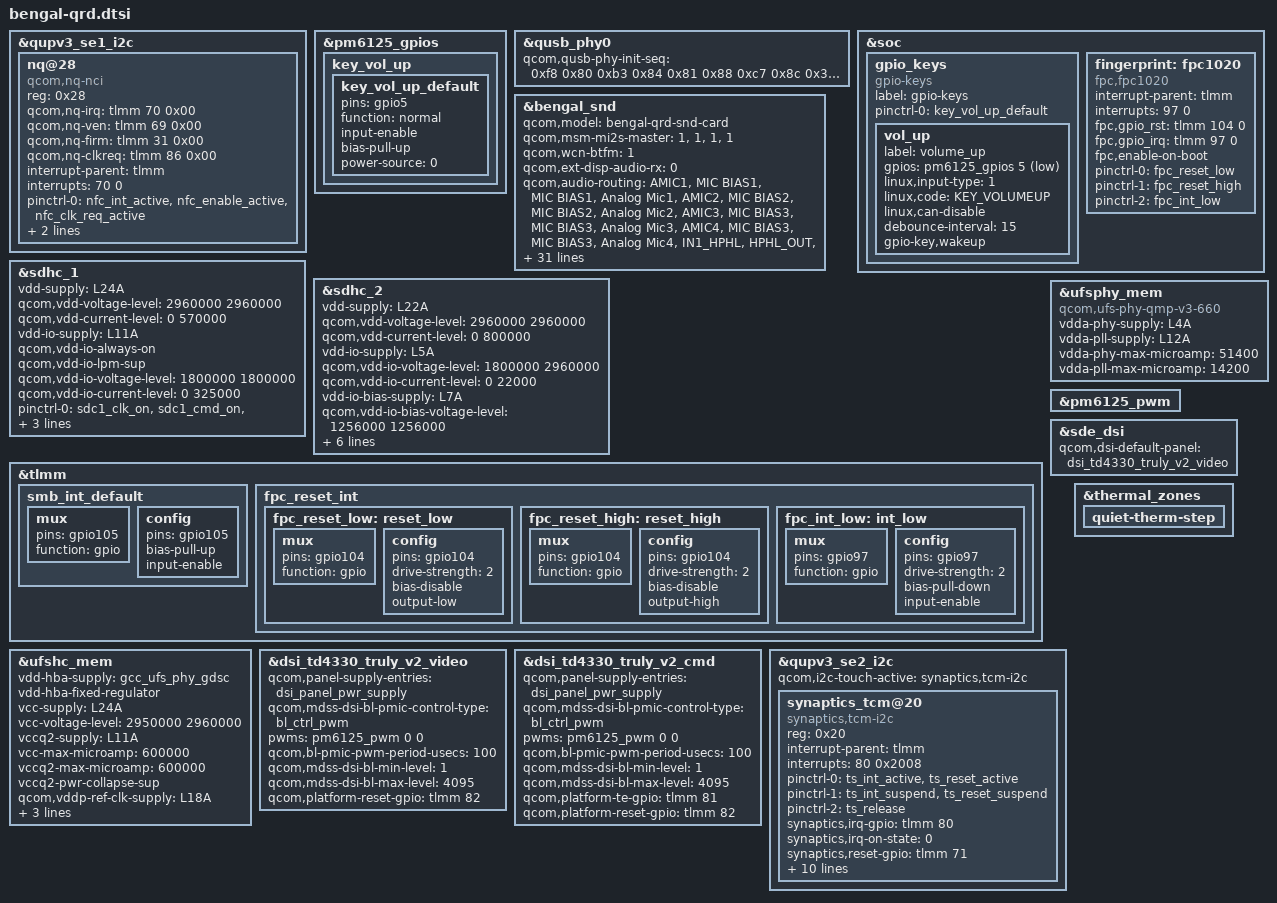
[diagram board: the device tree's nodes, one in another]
#include <dt-bindings/gpio/gpio.h>
#include <dt-bindings/iio/qcom,spmi-vadc.h>
#include <dt-bindings/input/input.h>
#include "bengal-thermal-overlay.dtsi"
#include "bengal-audio-overlay.dtsi"
#include "bengal-sde-display.dtsi"
#include "camera/bengal-camera-sensor-qrd.dtsi"

&qupv3_se1_i2c {
	status = "ok";
	#include "smb1355.dtsi"
};

&pm6125_gpios {
	key_vol_up {
		key_vol_up_default: key_vol_up_default {
			pins = "gpio5";
			function = "normal";
			input-enable;
			bias-pull-up;
			power-source = <0>;
		};
	};
};

&qusb_phy0 {
	qcom,qusb-phy-init-seq = <0xf8 0x80
				0xb3 0x84
				0x81 0x88
				0xc7 0x8c
				0x30 0x08
				0x79 0x0c
				0x21 0x10
				0x14 0x9c
				0x80 0x04
				0x9f 0x1c
				0x00 0x18>;
};

&soc {
	gpio_keys {
		compatible = "gpio-keys";
		label = "gpio-keys";

		pinctrl-names = "default";
		pinctrl-0 = <&key_vol_up_default>;

		vol_up {
			label = "volume_up";
			gpios = <&pm6125_gpios 5 GPIO_ACTIVE_LOW>;
			linux,input-type = <1>;
			linux,code = <KEY_VOLUMEUP>;
			linux,can-disable;
			debounce-interval = <15>;
			gpio-key,wakeup;
		};
	};
};

&bengal_snd {
	qcom,model = "bengal-qrd-snd-card";
	qcom,msm-mi2s-master = <1>, <1>, <1>, <1>;
	qcom,wcn-btfm = <1>;
	qcom,ext-disp-audio-rx = <0>;
	qcom,audio-routing =
		"AMIC1", "MIC BIAS1",
		"MIC BIAS1", "Analog Mic1",
		"AMIC2", "MIC BIAS2",
		"MIC BIAS2", "Analog Mic2",
		"AMIC3", "MIC BIAS3",
		"MIC BIAS3", "Analog Mic3",
		"AMIC4", "MIC BIAS3",
		"MIC BIAS3", "Analog Mic4",
		"IN1_HPHL", "HPHL_OUT",
		"IN2_HPHR", "HPHR_OUT",
		"IN3_AUX", "AUX_OUT",
		"SpkrMono WSA_IN", "AUX",
		"TX SWR_MIC0", "ADC1_OUTPUT",
		"TX SWR_MIC4", "ADC2_OUTPUT",
		"TX SWR_MIC5", "ADC3_OUTPUT",
		"TX SWR_MIC0", "VA_TX_SWR_CLK",
		"TX SWR_MIC1", "VA_TX_SWR_CLK",
		"TX SWR_MIC2", "VA_TX_SWR_CLK",
		"TX SWR_MIC3", "VA_TX_SWR_CLK",
		"TX SWR_MIC4", "VA_TX_SWR_CLK",
		"TX SWR_MIC5", "VA_TX_SWR_CLK",
		"TX SWR_MIC6", "VA_TX_SWR_CLK",
		"TX SWR_MIC7", "VA_TX_SWR_CLK",
		"TX SWR_MIC8", "VA_TX_SWR_CLK",
		"TX SWR_MIC9", "VA_TX_SWR_CLK",
		"TX SWR_MIC10", "VA_TX_SWR_CLK",
		"TX SWR_MIC11", "VA_TX_SWR_CLK",
		"RX_TX DEC0_INP", "TX DEC0 MUX",
		"RX_TX DEC1_INP", "TX DEC1 MUX",
		"RX_TX DEC2_INP", "TX DEC2 MUX",
		"RX_TX DEC3_INP", "TX DEC3 MUX",
		"TX_AIF1 CAP", "VA_TX_SWR_CLK",
		"TX_AIF2 CAP", "VA_TX_SWR_CLK",
		"TX_AIF3 CAP", "VA_TX_SWR_CLK",
		"VA SWR_MIC0", "ADC1_OUTPUT",
		"VA SWR_MIC4", "ADC2_OUTPUT",
		"VA SWR_MIC5", "ADC3_OUTPUT";
	qcom,msm-mbhc-hphl-swh = <1>;
	qcom,msm-mbhc-gnd-swh = <1>;
	asoc-codec  = <&stub_codec>, <&bolero>;
	asoc-codec-names = "msm-stub-codec.1", "bolero_codec";
	qcom,wsa-max-devs = <1>;
	qcom,wsa-devs = <&wsa881x_i2c_e>;
	qcom,wsa-aux-dev-prefix = "SpkrMono";
	qcom,codec-max-aux-devs = <1>;
	qcom,codec-aux-devs = <&wcd937x_codec>;
	qcom,msm_audio_ssr_devs = <&audio_apr>, <&q6core>, <&bolero>,
				<&lpi_tlmm>;
};

&qupv3_se1_i2c {
	status = "ok";
	#address-cells = <1>;
	#size-cells = <0>;
	nq@28 {
		compatible = "qcom,nq-nci";
		reg = <0x28>;
		qcom,nq-irq = <&tlmm 70 0x00>;
		qcom,nq-ven = <&tlmm 69 0x00>;
		qcom,nq-firm = <&tlmm 31 0x00>;
		qcom,nq-clkreq = <&tlmm 86 0x00>;
		interrupt-parent = <&tlmm>;
		interrupts = <70 0>;
		interrupt-names = "nfc_irq";
		pinctrl-names = "nfc_active", "nfc_suspend";
		pinctrl-0 = <&nfc_int_active &nfc_enable_active
				&nfc_clk_req_active>;
		pinctrl-1 = <&nfc_int_suspend &nfc_enable_suspend
				&nfc_clk_req_suspend>;
	};
};

&sdhc_1 {
	vdd-supply = <&L24A>;
	qcom,vdd-voltage-level = <2960000 2960000>;
	qcom,vdd-current-level = <0 570000>;

	vdd-io-supply = <&L11A>;
	qcom,vdd-io-always-on;
	qcom,vdd-io-lpm-sup;
	qcom,vdd-io-voltage-level = <1800000 1800000>;
	qcom,vdd-io-current-level = <0 325000>;

	pinctrl-names = "active", "sleep";
	pinctrl-0 = <&sdc1_clk_on &sdc1_cmd_on &sdc1_data_on
					&sdc1_rclk_on>;
	pinctrl-1 = <&sdc1_clk_off &sdc1_cmd_off &sdc1_data_off
					&sdc1_rclk_off>;

	status = "ok";
};

&sdhc_2 {
	vdd-supply = <&L22A>;
	qcom,vdd-voltage-level = <2960000 2960000>;
	qcom,vdd-current-level = <0 800000>;

	vdd-io-supply = <&L5A>;
	qcom,vdd-io-voltage-level = <1800000 2960000>;
	qcom,vdd-io-current-level = <0 22000>;

	vdd-io-bias-supply = <&L7A>;
	qcom,vdd-io-bias-voltage-level = <1256000 1256000>;
	qcom,vdd-io-bias-current-level = <0 6000>;

	pinctrl-names = "active", "sleep";
	pinctrl-0 = <&sdc2_clk_on  &sdc2_cmd_on &sdc2_data_on &sdc2_cd_on>;
	pinctrl-1 = <&sdc2_clk_off &sdc2_cmd_off &sdc2_data_off &sdc2_cd_off>;

	cd-gpios = <&tlmm 88 GPIO_ACTIVE_LOW>;

	status = "ok";
};

&tlmm {
	smb_int_default: smb_int_default {
		mux {
			pins = "gpio105";
			function = "gpio";
		};

		config {
			pins = "gpio105";
			bias-pull-up;
			input-enable;
		};
	};
};

&ufsphy_mem {
	compatible = "qcom,ufs-phy-qmp-v3-660";

	vdda-phy-supply = <&L4A>; /* 0.9v */
	vdda-pll-supply = <&L12A>; /* 1.8v */
	vdda-phy-max-microamp = <51400>;
	vdda-pll-max-microamp = <14200>;

	status = "ok";
};

&ufshc_mem {
	vdd-hba-supply = <&gcc_ufs_phy_gdsc>;
	vdd-hba-fixed-regulator;
	vcc-supply = <&L24A>;
	vcc-voltage-level = <2950000 2960000>;
	vccq2-supply = <&L11A>;
	vcc-max-microamp = <600000>;
	vccq2-max-microamp = <600000>;
	vccq2-pwr-collapse-sup;

	qcom,vddp-ref-clk-supply = <&L18A>;
	qcom,vddp-ref-clk-max-microamp = <100>;
	qcom,vddp-ref-clk-min-uV = <1232000>;
	qcom,vddp-ref-clk-max-uV = <1232000>;

	status = "ok";
};

&pm6125_pwm {
	status = "ok";
};

&dsi_td4330_truly_v2_video {
	qcom,panel-supply-entries = <&dsi_panel_pwr_supply>;
	qcom,mdss-dsi-bl-pmic-control-type = "bl_ctrl_pwm";
	pwms = <&pm6125_pwm 0 0>;
	qcom,bl-pmic-pwm-period-usecs = <100>;
	qcom,mdss-dsi-bl-min-level = <1>;
	qcom,mdss-dsi-bl-max-level = <4095>;
	qcom,platform-reset-gpio = <&tlmm 82 0>;
};

&dsi_td4330_truly_v2_cmd {
	qcom,panel-supply-entries = <&dsi_panel_pwr_supply>;
	qcom,mdss-dsi-bl-pmic-control-type = "bl_ctrl_pwm";
	pwms = <&pm6125_pwm 0 0>;
	qcom,bl-pmic-pwm-period-usecs = <100>;
	qcom,mdss-dsi-bl-min-level = <1>;
	qcom,mdss-dsi-bl-max-level = <4095>;
	qcom,platform-te-gpio = <&tlmm 81 0>;
	qcom,platform-reset-gpio = <&tlmm 82 0>;
};

&sde_dsi {
	qcom,dsi-default-panel = <&dsi_td4330_truly_v2_video>;
};

&qupv3_se2_i2c {
	status = "okay";
	qcom,i2c-touch-active="synaptics,tcm-i2c";

	synaptics_tcm@20 {
		compatible = "synaptics,tcm-i2c";
		reg = <0x20>;
		interrupt-parent = <&tlmm>;
		interrupts = <80 0x2008>;
		pinctrl-names = "pmx_ts_active","pmx_ts_suspend",
			"pmx_ts_release";
		pinctrl-0 = <&ts_int_active &ts_reset_active>;
		pinctrl-1 = <&ts_int_suspend &ts_reset_suspend>;
		pinctrl-2 = <&ts_release>;
		synaptics,irq-gpio = <&tlmm 80 0x2008>;
		synaptics,irq-on-state = <0>;
		synaptics,reset-gpio = <&tlmm 71 0x00>;
		synaptics,reset-on-state = <0>;
		synaptics,reset-active-ms = <20>;
		synaptics,reset-delay-ms = <200>;
		synaptics,power-delay-ms = <200>;
		synaptics,ubl-i2c-addr = <0x20>;
		synaptics,extend_report;
		synaptics,firmware-name = "synaptics_firmware_k.img";

		panel = <&dsi_td4330_truly_v2_video &dsi_td4330_truly_v2_cmd>;
	};
};

&thermal_zones {
	quiet-therm-step {
		status = "ok";
	};
};

&tlmm {
	fpc_reset_int: fpc_reset_int {
		fpc_reset_low: reset_low {
			mux {
				pins = "gpio104";
				function = "gpio";
			};

			config {
				pins = "gpio104";
				drive-strength = <2>;
				bias-disable;
				output-low;
			};
		};

		fpc_reset_high: reset_high {
			mux {
				pins = "gpio104";
				function = "gpio";
			};

			config {
				pins = "gpio104";
				drive-strength = <2>;
				bias-disable;
				output-high;
			};
		};

		fpc_int_low: int_low {
			mux {
				pins = "gpio97";
				function = "gpio";
			};

			config {
				pins = "gpio97";
				drive-strength = <2>;
				bias-pull-down;
				input-enable;
			};
		};
	};
};

&soc {
	fingerprint: fpc1020 {
		compatible = "fpc,fpc1020";
		interrupt-parent = <&tlmm>;
		interrupts = <97 0>;
		fpc,gpio_rst = <&tlmm 104 0>;
		fpc,gpio_irq = <&tlmm 97 0>;
		fpc,enable-on-boot;
		pinctrl-names = "fpc1020_reset_reset",
				"fpc1020_reset_active",
				"fpc1020_irq_active";
		pinctrl-0 = <&fpc_reset_low>;
		pinctrl-1 = <&fpc_reset_high>;
		pinctrl-2 = <&fpc_int_low>;
	};
};
